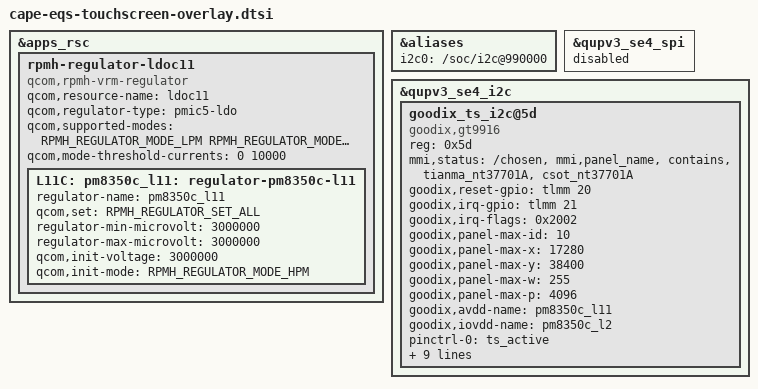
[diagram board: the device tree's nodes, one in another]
/*
 * Copyright (c) 2019, The Linux Foundation. All rights reserved.
 *
 * This program is free software; you can redistribute it and/or modify
 * it under the terms of the GNU General Public License version 2 and
 * only version 2 as published by the Free Software Foundation.
 *
 * This program is distributed in the hope that it will be useful,
 * but WITHOUT ANY WARRANTY; without even the implied warranty of
 * MERCHANTABILITY or FITNESS FOR A PARTICULAR PURPOSE.  See the
 * GNU General Public License for more details.
 */
#include <dt-bindings/clock/qcom,rpmh.h>

&apps_rsc {
	rpmh-regulator-ldoc11 {
		compatible = "qcom,rpmh-vrm-regulator";
		qcom,resource-name = "ldoc11";
		qcom,regulator-type = "pmic5-ldo";
		qcom,supported-modes =
			<RPMH_REGULATOR_MODE_LPM
			RPMH_REGULATOR_MODE_HPM>;
		qcom,mode-threshold-currents = <0 10000>;
		L11C:
		pm8350c_l11: regulator-pm8350c-l11 {
			regulator-name = "pm8350c_l11";
			qcom,set = <RPMH_REGULATOR_SET_ALL>;
			regulator-min-microvolt = <3000000>;
			regulator-max-microvolt = <3000000>;
			qcom,init-voltage = <3000000>;
			qcom,init-mode = <RPMH_REGULATOR_MODE_HPM>;
		};
	};
};

&aliases {
	i2c0 = "/soc/i2c@990000";
};

&qupv3_se4_spi {
	status = "disabled";
};

&qupv3_se4_i2c {
	#address-cells = <1>;
	#size-cells = <0>;

	status = "ok";
	goodix_ts_i2c@5d {
		status = "ok";
		compatible = "goodix,gt9916";
		reg = <0x5d>;
		mmi,status = "/chosen","mmi,panel_name","contains","tianma_nt37701A", "csot_nt37701A";
		goodix,reset-gpio = <&tlmm 20 0x0>;
		goodix,irq-gpio = <&tlmm 21 0x2002>;
		goodix,irq-flags = <0x2002>; /* 1:trigger rising, 2:trigger falling;*/
		goodix,panel-max-id = <10>;
		goodix,panel-max-x = <17280>;
		goodix,panel-max-y = <38400>;
		goodix,panel-max-w = <255>;
		goodix,panel-max-p = <4096>;
		goodix,avdd-name = "pm8350c_l11";
		goodix,iovdd-name = "pm8350c_l2";
		pinctrl-names = "pmx_ts_active", "pmx_ts_suspend", "pmx_ts_release";
		pinctrl-0 = <&ts_active>;
		pinctrl-1 = <&ts_int_suspend &ts_reset_suspend>;
		pinctrl-2 = <&ts_release>;
		mmi,enable-gestures;
		goodix,edge-ctrl;
		mmi,power-off-suspend;
		mmi,usb-charger-detection;
		goodix,interpolation-ctrl;
		mmi,fod_coords = <540 2152>;
		mmi,supported_gesture_type = <0x07>;
	};
};
